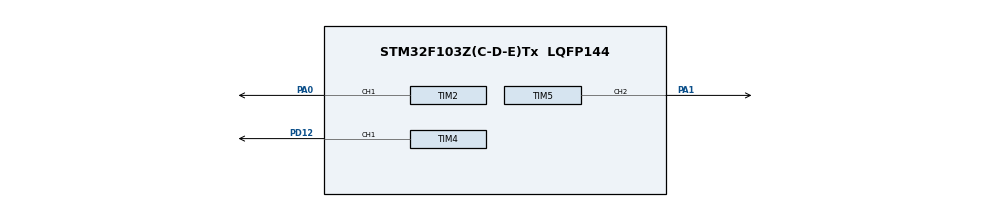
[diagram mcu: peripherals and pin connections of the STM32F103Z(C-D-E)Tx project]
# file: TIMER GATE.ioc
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Mcu.Family=STM32F1
Mcu.Name=STM32F103Z(C-D-E)Tx
Mcu.Package=LQFP144
NVIC.PriorityGroup=NVIC_PRIORITYGROUP_4
NVIC.TIM2_IRQn=true\:0\:0\:false\:false\:true
OSC_IN.Mode=HSE-External-Oscillator
OSC_IN.Signal=RCC_OSC_IN
OSC_OUT.Mode=HSE-External-Oscillator
OSC_OUT.Signal=RCC_OSC_OUT
PA0-WKUP.Signal=S_TIM2_CH1_ETR
PA1.Signal=S_TIM5_CH2
PA13.Mode=Serial_Wire
PA13.Signal=SYS_JTMS-SWDIO
PA14.Mode=Serial_Wire
PA14.Signal=SYS_JTCK-SWCLK
PC14-OSC32_IN.Mode=LSE-External-Oscillator
PC14-OSC32_IN.Signal=RCC_OSC32_IN
PC15-OSC32_OUT.Mode=LSE-External-Oscillator
PC15-OSC32_OUT.Signal=RCC_OSC32_OUT
PD12.Signal=S_TIM4_CH1
ProjectManager.HeapSize=0x200
ProjectManager.StackSize=0x400
ProjectManager.TargetToolchain=MDK-ARM V5
RCC.APB1Freq_Value=8000000
RCC.APB2Freq_Value=8000000
SH.S_TIM2_CH1_ETR.0=TIM2_CH1,PWM Generation1 CH1
SH.S_TIM4_CH1.0=TIM4_CH1,Output Compare1 CH1
SH.S_TIM5_CH2.0=TIM5_CH2,PWM Generation2 CH2
TIM2.Period=20
TIM2.Prescaler=7200
TIM2.Pulse-PWM\ Generation1\ CH1=10
TIM2.TIM_MasterSlaveMode=TIM_MASTERSLAVEMODE_ENABLE
TIM4.Period=2000-1
TIM4.Prescaler=7200-1
TIM4.TIM_MasterOutputTrigger=TIM_TRGO_OC1
TIM4.TIM_MasterSlaveMode=TIM_MASTERSLAVEMODE_ENABLE
TIM5.Channel-PWM\ Generation2\ CH2=TIM_CHANNEL_2
VP_CRC_VS_CRC.Mode=CRC_Activate
VP_TIM2_VS_ClockSourceITR.Mode=TriggerSource_ITR3
VP_TIM2_VS_ControllerModeGated.Mode=Gated Mode
VP_TIM4_VS_OPM.Mode=OPM_bit
VP_TIM5_VS_ClockSourceITR.Mode=TriggerSource_ITR3
VP_TIM5_VS_ControllerModeGated.Mode=Gated Mode
VP_TIM8_VS_OPM.Mode=OPM_bit
VP_TIM8_VS_no_output1.Mode=Output Compare1 No Output
board=TIMER GATE

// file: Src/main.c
/**
  ******************************************************************************
  * File Name          : main.c
  * Description        : Main program body
  ******************************************************************************
  *
  * COPYRIGHT(c) 2016 STMicroelectronics
  *
  * Redistribution and use in source and binary forms, with or without modification,
  * are permitted provided that the following conditions are met:
  *   1. Redistributions of source code must retain the above copyright notice,
  *      this list of conditions and the following disclaimer.
  *   2. Redistributions in binary form must reproduce the above copyright notice,
  *      this list of conditions and the following disclaimer in the documentation
  *      and/or other materials provided with the distribution.
  *   3. Neither the name of STMicroelectronics nor the names of its contributors
  *      may be used to endorse or promote products derived from this software
  *      without specific prior written permission.
  *
  * THIS SOFTWARE IS PROVIDED BY THE COPYRIGHT HOLDERS AND CONTRIBUTORS "AS IS"
  * AND ANY EXPRESS OR IMPLIED WARRANTIES, INCLUDING, BUT NOT LIMITED TO, THE
  * IMPLIED WARRANTIES OF MERCHANTABILITY AND FITNESS FOR A PARTICULAR PURPOSE ARE
  * DISCLAIMED. IN NO EVENT SHALL THE COPYRIGHT HOLDER OR CONTRIBUTORS BE LIABLE
  * FOR ANY DIRECT, INDIRECT, INCIDENTAL, SPECIAL, EXEMPLARY, OR CONSEQUENTIAL
  * DAMAGES (INCLUDING, BUT NOT LIMITED TO, PROCUREMENT OF SUBSTITUTE GOODS OR
  * SERVICES; LOSS OF USE, DATA, OR PROFITS; OR BUSINESS INTERRUPTION) HOWEVER
  * CAUSED AND ON ANY THEORY OF LIABILITY, WHETHER IN CONTRACT, STRICT LIABILITY,
  * OR TORT (INCLUDING NEGLIGENCE OR OTHERWISE) ARISING IN ANY WAY OUT OF THE USE
  * OF THIS SOFTWARE, EVEN IF ADVISED OF THE POSSIBILITY OF SUCH DAMAGE.
  *
  ******************************************************************************
  */
#include "stm32f1xx_hal.h"
#include "crc.h"
#include "tim.h"
#include "gpio.h"

/* USER CODE BEGIN PV */
/* Private variables ---------------------------------------------------------*/

/* USER CODE END PV */

void SystemClock_Config(void);
void Error_Handler(void);

/* USER CODE BEGIN PFP */
/* Private function prototypes -----------------------------------------------*/

/* USER CODE END PFP */

int main(void)
{

  /* MCU Configuration----------------------------------------------------------*/

  /* Reset of all peripherals, Initializes the Flash interface and the Systick. */
  HAL_Init();

  /* Configure the system clock */
  SystemClock_Config();

  /* Initialize all configured peripherals */
  MX_GPIO_Init();
  MX_CRC_Init();
  MX_TIM2_Init();
  MX_TIM4_Init();
  MX_TIM5_Init();
  MX_TIM8_Init();

  /* Infinite loop */
  while (1)
  {

  /* USER CODE BEGIN 3 */
		HAL_TIM_OnePulse_Start(&htim4,TIM_CHANNEL_1);
		HAL_Delay(500);
  }
  /* USER CODE END 3 */

}

/** System Clock Configuration
*/
void SystemClock_Config(void)
{

  RCC_OscInitTypeDef RCC_OscInitStruct;
  RCC_ClkInitTypeDef RCC_ClkInitStruct;

  RCC_OscInitStruct.OscillatorType = RCC_OSCILLATORTYPE_HSI;
  RCC_OscInitStruct.HSIState = RCC_HSI_ON;
  RCC_OscInitStruct.HSICalibrationValue = 16;
  RCC_OscInitStruct.PLL.PLLState = RCC_PLL_NONE;
  if (HAL_RCC_OscConfig(&RCC_OscInitStruct) != HAL_OK)
  {
    Error_Handler();
  }

  RCC_ClkInitStruct.ClockType = RCC_CLOCKTYPE_HCLK|RCC_CLOCKTYPE_SYSCLK
                              |RCC_CLOCKTYPE_PCLK1|RCC_CLOCKTYPE_PCLK2;
  RCC_ClkInitStruct.SYSCLKSource = RCC_SYSCLKSOURCE_HSI;
  RCC_ClkInitStruct.AHBCLKDivider = RCC_SYSCLK_DIV1;
  RCC_ClkInitStruct.APB1CLKDivider = RCC_HCLK_DIV1;
  RCC_ClkInitStruct.APB2CLKDivider = RCC_HCLK_DIV1;
  if (HAL_RCC_ClockConfig(&RCC_ClkInitStruct, FLASH_LATENCY_0) != HAL_OK)
  {
    Error_Handler();
  }

  HAL_SYSTICK_Config(HAL_RCC_GetHCLKFreq()/1000);

  HAL_SYSTICK_CLKSourceConfig(SYSTICK_CLKSOURCE_HCLK);

  /* SysTick_IRQn interrupt configuration */
  HAL_NVIC_SetPriority(SysTick_IRQn, 0, 0);
}

void Error_Handler(void)
{
  while(1)
  {
  }
}

/************************ (C) COPYRIGHT STMicroelectronics *****END OF FILE****/
